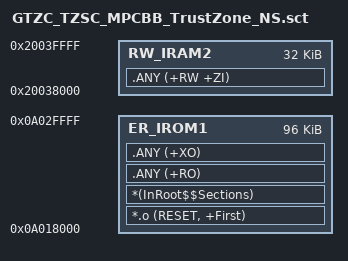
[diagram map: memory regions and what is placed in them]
; *************************************************************
; *** Scatter-Loading Description File generated by uVision ***
; *************************************************************

LR_IROM1 0x0A018000 0x18000  {    ; load region size_region
  ER_IROM1 0x0A018000 0x18000  {  ; load address = execution address
   *.o (RESET, +First)
   *(InRoot$$Sections)
   .ANY (+RO)
   .ANY (+XO)
  }
  RW_IRAM2 0x20038000 0x0008000  {
   .ANY (+RW +ZI)
  }
}

